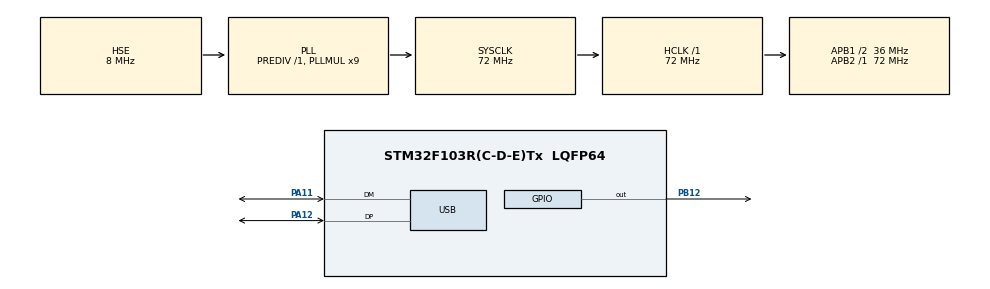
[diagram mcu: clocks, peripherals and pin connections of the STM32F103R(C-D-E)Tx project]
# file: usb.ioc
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Mcu.Family=STM32F1
Mcu.Name=STM32F103R(C-D-E)Tx
Mcu.Package=LQFP64
NVIC.PriorityGroup=NVIC_PRIORITYGROUP_4
NVIC.USB_LP_CAN1_RX0_IRQn=true\:0\:0\:false
PA11.Mode=Device
PA11.Signal=USB_DM
PA12.Mode=Device
PA12.Signal=USB_DP
PB12.Signal=GPIO_Output
PD0-OSC_IN.Mode=HSE-External-Oscillator
PD0-OSC_IN.Signal=RCC_OSC_IN
PD1-OSC_OUT.Mode=HSE-External-Oscillator
PD1-OSC_OUT.Signal=RCC_OSC_OUT
ProjectManager.TargetToolchain=MDK-ARM 4.73
RCC.AHBFreq_Value=72000000
RCC.APB1CLKDivider=RCC_HCLK_DIV2
RCC.APB1Freq_Value=36000000
RCC.APB1TimFreq_Value=72000000
RCC.APB2Freq_Value=72000000
RCC.APB2TimFreq_Value=72000000
RCC.HCLKFreq_Value=72000000
RCC.HSIState=RCC_HSI_ON
RCC.PLLMUL=RCC_PLL_MUL9
RCC.PLLSourceVirtual=RCC_PLLSOURCE_HSE
RCC.SYSCLKFreq_VALUE=72000000
RCC.SYSCLKSource=RCC_SYSCLKSOURCE_PLLCLK
RCC.USBFreq_Value=48000000
RCC.USBPrescaler=RCC_USBPLLCLK_DIV1_5
USB_DEVICE.CLASS_NAME-CDC_FS=CDC
USB_DEVICE.USBD_CDC_INTERVAL-CDC_FS=1000
USB_DEVICE.USBD_HandleTypeDef-CDC_FS=hUsbDeviceFS
USB_DEVICE.USBD_MAX_STR_DESC_SIZ-CDC_FS=64
USB_DEVICE.VirtualMode-CDC_FS=Cdc
USB_DEVICE.VirtualModeFS-CDC_FS=Cdc_FS
VP_USB_DEVICE_VS_USB_DEVICE_CDC_FS.Mode=CDC_FS

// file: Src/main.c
/**
  ******************************************************************************
  * File Name          : main.c
  * Date               : 19/12/2016 16:36:45
  * Description        : Main program body
  ******************************************************************************
  *
  * COPYRIGHT(c) 2016 STMicroelectronics
  *
  * Redistribution and use in source and binary forms, with or without modification,
  * are permitted provided that the following conditions are met:
  *   1. Redistributions of source code must retain the above copyright notice,
  *      this list of conditions and the following disclaimer.
  *   2. Redistributions in binary form must reproduce the above copyright notice,
  *      this list of conditions and the following disclaimer in the documentation
  *      and/or other materials provided with the distribution.
  *   3. Neither the name of STMicroelectronics nor the names of its contributors
  *      may be used to endorse or promote products derived from this software
  *      without specific prior written permission.
  *
  * THIS SOFTWARE IS PROVIDED BY THE COPYRIGHT HOLDERS AND CONTRIBUTORS "AS IS"
  * AND ANY EXPRESS OR IMPLIED WARRANTIES, INCLUDING, BUT NOT LIMITED TO, THE
  * IMPLIED WARRANTIES OF MERCHANTABILITY AND FITNESS FOR A PARTICULAR PURPOSE ARE
  * DISCLAIMED. IN NO EVENT SHALL THE COPYRIGHT HOLDER OR CONTRIBUTORS BE LIABLE
  * FOR ANY DIRECT, INDIRECT, INCIDENTAL, SPECIAL, EXEMPLARY, OR CONSEQUENTIAL
  * DAMAGES (INCLUDING, BUT NOT LIMITED TO, PROCUREMENT OF SUBSTITUTE GOODS OR
  * SERVICES; LOSS OF USE, DATA, OR PROFITS; OR BUSINESS INTERRUPTION) HOWEVER
  * CAUSED AND ON ANY THEORY OF LIABILITY, WHETHER IN CONTRACT, STRICT LIABILITY,
  * OR TORT (INCLUDING NEGLIGENCE OR OTHERWISE) ARISING IN ANY WAY OUT OF THE USE
  * OF THIS SOFTWARE, EVEN IF ADVISED OF THE POSSIBILITY OF SUCH DAMAGE.
  *
  ******************************************************************************
  */

#include "stm32f1xx_hal.h"
#include "usb_device.h"
#include "ringbuffer.h"

uint8_t working_buffer[BUFFER_SIZE];
struct rb working_rb;

void SystemClock_Config(void);
static void MX_GPIO_Init(void);

void delayms(int ms)
{
	for(int i=0;i<ms;i++)
	{
		int delay=10000;
		while(delay-- >=0){}
	}
}

int main(void)
{

  /* MCU Configuration----------------------------------------------------------*/

  /* Reset of all peripherals, Initializes the Flash interface and the Systick. */
  HAL_Init();

  /* Configure the system clock */
  SystemClock_Config();

  /* Initialize all configured peripherals */
  MX_GPIO_Init();
  MX_USB_DEVICE_Init();
  rb_init(&working_rb, working_buffer, BUFFER_SIZE);

  /* USER CODE BEGIN 3 */
  /* Infinite loop */
	uint8_t buf=0x32;
	char byte[1];
	#define APP_RX_DATA_SIZE  4
extern	uint8_t UserRxBufferFS[APP_RX_DATA_SIZE];
  while (1)
  {
	//	USBD_CDC_SetTxBuffer(&hUsbDeviceFS, (uint8_t*)UserRxBufferFS, 7);
	//	USBD_CDC_TransmitPacket(&hUsbDeviceFS);
/*		if (VCP_read(&byte, 1) != 1)
				continue;
		VCP_write("\r\nYou typed ", 12);
		VCP_write(&byte, 1);
		VCP_write("\r\n", 2);	*/
		if(rb_get(&working_rb, byte, 1) != 0)
		{
			CDC_Transmit_FS(byte,1);
		//	HAL_Delay(300);
			HAL_GPIO_TogglePin(GPIOB,GPIO_PIN_12);
		}
	HAL_Delay(10);
  }
  /* USER CODE END 3 */

}

/** System Clock Configuration
*/
void SystemClock_Config(void)
{

  RCC_OscInitTypeDef RCC_OscInitStruct;
  RCC_ClkInitTypeDef RCC_ClkInitStruct;
  RCC_PeriphCLKInitTypeDef PeriphClkInit;

  RCC_OscInitStruct.OscillatorType = RCC_OSCILLATORTYPE_HSE;
  RCC_OscInitStruct.HSEState = RCC_HSE_ON;
  RCC_OscInitStruct.HSEPredivValue = RCC_HSE_PREDIV_DIV1;
  RCC_OscInitStruct.PLL.PLLState = RCC_PLL_ON;
  RCC_OscInitStruct.PLL.PLLSource = RCC_PLLSOURCE_HSE;
  RCC_OscInitStruct.PLL.PLLMUL = RCC_PLL_MUL9;
  HAL_RCC_OscConfig(&RCC_OscInitStruct);

  RCC_ClkInitStruct.ClockType = RCC_CLOCKTYPE_SYSCLK|RCC_CLOCKTYPE_PCLK1;
  RCC_ClkInitStruct.SYSCLKSource = RCC_SYSCLKSOURCE_PLLCLK;
  RCC_ClkInitStruct.AHBCLKDivider = RCC_SYSCLK_DIV1;
  RCC_ClkInitStruct.APB1CLKDivider = RCC_HCLK_DIV2;
  RCC_ClkInitStruct.APB2CLKDivider = RCC_HCLK_DIV1;
  HAL_RCC_ClockConfig(&RCC_ClkInitStruct, FLASH_LATENCY_2);

  PeriphClkInit.PeriphClockSelection = RCC_PERIPHCLK_USB;
  PeriphClkInit.UsbClockSelection = RCC_USBPLLCLK_DIV1_5;
  HAL_RCCEx_PeriphCLKConfig(&PeriphClkInit);

  __HAL_RCC_AFIO_CLK_ENABLE();

}

/** Configure pins as
        * Analog
        * Input
        * Output
        * EVENT_OUT
        * EXTI
*/
void MX_GPIO_Init(void)
{

  GPIO_InitTypeDef GPIO_InitStruct;

  /* GPIO Ports Clock Enable */
  __GPIOD_CLK_ENABLE();
  __GPIOB_CLK_ENABLE();
  __GPIOA_CLK_ENABLE();

  /*Configure GPIO pin : PB12 */
  GPIO_InitStruct.Pin = GPIO_PIN_12;
  GPIO_InitStruct.Mode = GPIO_MODE_OUTPUT_PP;
  GPIO_InitStruct.Speed = GPIO_SPEED_LOW;
  HAL_GPIO_Init(GPIOB, &GPIO_InitStruct);

}

/************************ (C) COPYRIGHT STMicroelectronics *****END OF FILE****/
